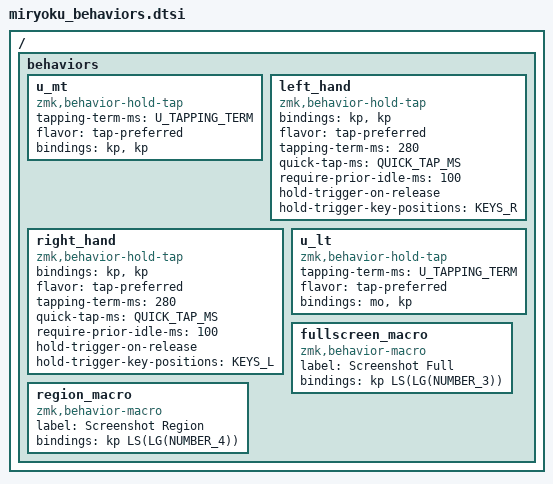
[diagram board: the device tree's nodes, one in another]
// Copyright 2022 Manna Harbour
// https://github.com/manna-harbour/miryoku

#define QUICK_TAP_MS 175
#define KEYS_L 57 56 55 72 73 74 5 6 7 8 16 17 18 19 20 28 29 30 31 32 40 41 42 43 44 58 59 60 61 62 75 76 77 78 9 21 33 45 63 79 52 53 54 70 71 69
#define KEYS_R 52 53 54 71 70 69 0 1 10 11 12 13 14 22 23 24 25 26 27 34 35 36 37 38 39 46 47 48 49 50 51 64 65 66 67 68 15 4 2 3 55 56 57 72 73 74

/ {
  behaviors {
    u_mt: u_mt {
      compatible = "zmk,behavior-hold-tap";
      #binding-cells = <2>;
      tapping-term-ms = <U_TAPPING_TERM>;
      flavor = "tap-preferred";
      bindings = <&kp>, <&kp>;
    };
    left_hand: left_hand {
      compatible = "zmk,behavior-hold-tap";
      #binding-cells = <2>;
      bindings = <&kp>, <&kp>;
      flavor = "tap-preferred";
      tapping-term-ms = <280>;
      quick-tap-ms = <QUICK_TAP_MS>;
      require-prior-idle-ms = <100>;
      hold-trigger-on-release;
      hold-trigger-key-positions = <KEYS_R>;
    };
    right_hand: right_hand {
      compatible = "zmk,behavior-hold-tap";
      #binding-cells = <2>;
      bindings = <&kp>, <&kp>;
      flavor = "tap-preferred";
      tapping-term-ms = <280>;
      quick-tap-ms = <QUICK_TAP_MS>;
      require-prior-idle-ms = <100>;
      hold-trigger-on-release;
      hold-trigger-key-positions = <KEYS_L>;
    };
    u_lt: u_lt {
      compatible = "zmk,behavior-hold-tap";
      #binding-cells = <2>;
      tapping-term-ms = <U_TAPPING_TERM>;
      flavor = "tap-preferred";
      bindings = <&mo>, <&kp>;
    };
    fullscreen_macro: fullscreen_macro {
      compatible = "zmk,behavior-macro";
      label = "Screenshot Full";
      #binding-cells = <0>;
      bindings = <&kp LS(LG(NUMBER_3))>;
    };
    region_macro: region_macro {
      compatible = "zmk,behavior-macro";
      label = "Screenshot Region";
      #binding-cells = <0>;
      bindings = <&kp LS(LG(NUMBER_4))>;
    };
  };
};
